# TPCC register map
Vendor: Texas Instruments
Registers are 32-bit, read-write, reset values left out (the file's numbers can be read two ways) unless marked. A register's access mark holds for its fields unless they carry their own. Offsets are as the file gives them; [hi:lo] are bit positions; {n}, {i} and the like mark numbered series; 'fields as' and 'values as' point back to an identical list.

## TPCC (part 2 of 2)
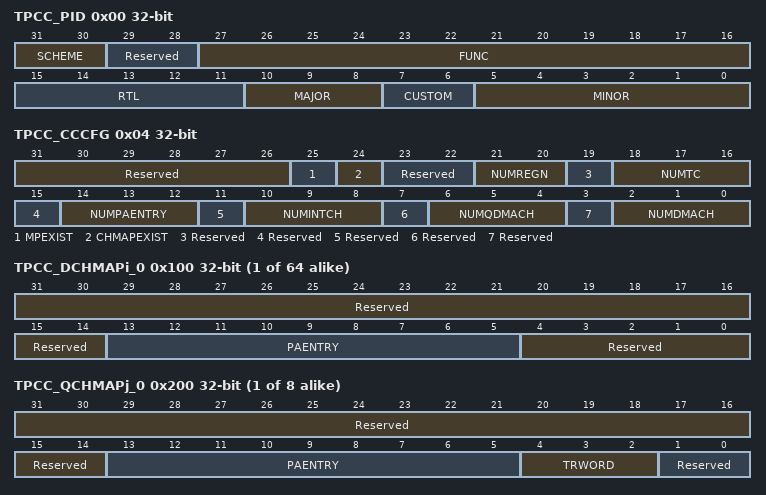
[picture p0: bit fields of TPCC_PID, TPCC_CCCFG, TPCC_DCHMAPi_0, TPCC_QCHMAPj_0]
0x00 TPCC_PID ro — Peripheral ID Register
  [31:30] SCHEME — PID scheme:Used to distinguish between old ID scheme and current.Spare bit to encode future schemes EDMA uses new scheme, indicated with value of 0x1. .
  [29:28] Reserved — Read returns 0.
  [27:16] FUNC — Function indicates a software-compatible module family.
  [15:11] RTL — RTL version
  [10:8] MAJOR — Major revision
  [7:6] CUSTOM — Custom revision field: Not used on this version of EDMA.
  [5:0] MINOR — Minor revision
0x04 TPCC_CCCFG ro — CC Configuration Register
  [31:26] Reserved — Read returns 0.
  [25] MPEXIST — Memory Protection ExistenceMPEXIST = 0: No memory protection.MPEXIST = 1: Memory Protection logic included.
  [24] CHMAPEXIST — Channel Mapping ExistenceCHMAPEXIST = 0: No Channel mapping.CHMAPEXIST = 1: Channel mapping logic included.
  [23:22] Reserved — Read returns 0.
  [21:20] NUMREGN — Number of MP and Shadow regions
    0=NUMREGN_0_r (0 Regions); 1=NUMREGN_1_r (2 Regions); 2=NUMREGN_2_r (4 Regions); 3=NUMREGN_3_r (8 Regions)
  [19] Reserved — Read returns 0.
  [18:16] NUMTC — Number of Queues/Number of TCs
    {v}=NUMTC_{v}_r ({v+1} TC/Event Queue) (v=0..7)
  [15] Reserved — Read returns 0.
  [14:12] NUMPAENTRY — Number of PaRAM entries
    0=NUMPAENTRY_0_r (16 entries); 1=NUMPAENTRY_1_r (32 entries (unsupported setting)); 2=NUMPAENTRY_2_r (64 entries); 3=NUMPAENTRY_3_r (128 entries); 4=NUMPAENTRY_4_r (256 entries); 5=NUMPAENTRY_5_r (512 entries)
  [11] Reserved — Read returns 0.
  [10:8] NUMINTCH — Number of Interrupt Channels
    1=NUMINTCH_1_r (8 Interrupt channels); 2=NUMINTCH_2_r (16 Interrupt channels); 3=NUMINTCH_3_r (32 Interrupt channels); 4=NUMINTCH_4_r (64 Interrupt channels)
  [7] Reserved — Read returns 0.
  [6:4] NUMQDMACH — Number of QDMA Channels
    0=NUMQDMACH_0_r (No QDMA Channels); 1=NUMQDMACH_1_r (2 QDMA Channels); 2=NUMQDMACH_2_r (4 QDMA Channels); 3=NUMQDMACH_3_r (6 QDMA Channels); 4=NUMQDMACH_4_r (8 QDMA Channels)
  [3] Reserved — Read returns 0.
  [2:0] NUMDMACH — Number of DMA Channels
    0=NUMDMACH_0_r (No DMA Channels); 1=NUMDMACH_1_r (4 DMA Channels); 2=NUMDMACH_2_r (8 DMA Channels); 3=NUMDMACH_3_r (16 DMA Channels); 4=NUMDMACH_4_r (32 DMA Channels); 5=NUMDMACH_5_r (64 DMA Channels)
{0x100+4i} TPCC_DCHMAPi_{i} (i=0..63) — DMA Channel i Mapping Register
  [31:14] Reserved — Write 0s for future compatibility.Read returns 0.
  [13:5] PAENTRY — PaRAM Entry number for DMA Channel i.
  [4:0] Reserved — Write 0s for future compatibility.Read returns 0.
{0x200+4i} TPCC_QCHMAPj_{i} (i=0..7) — QDMA Channel i Mapping Register
  [31:14] Reserved — Write 0s for future compatibility.Read returns 0.
  [13:5] PAENTRY — PaRAM Entry number for QDMA Channel i.
  [4:2] TRWORD — TRWORD points to the specific trigger word of the PaRAM Entry defined by PAENTRY. A write to the trigger word results in a QDMA Event being recognized.
  [1:0] Reserved — Write 0s for future compatibility.Read returns 0.
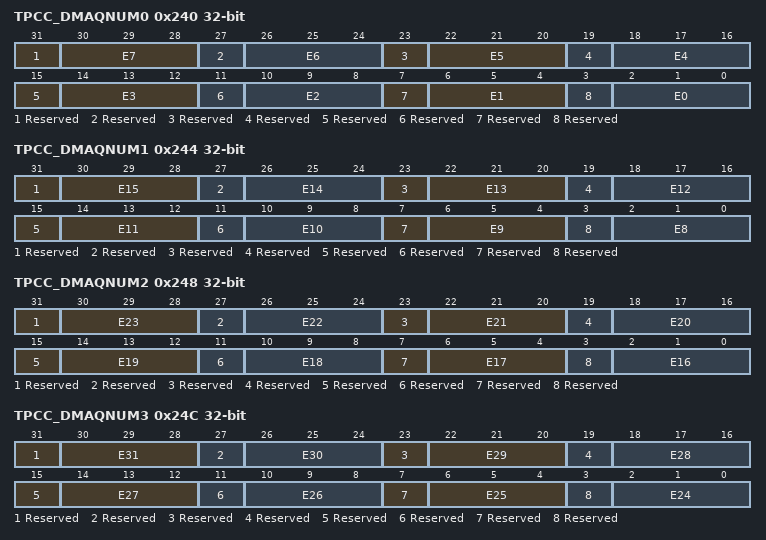
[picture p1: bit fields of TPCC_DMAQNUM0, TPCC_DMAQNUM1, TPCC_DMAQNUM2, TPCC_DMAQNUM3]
0x240 TPCC_DMAQNUM0 — DMA Queue Number Register 0Contains the Event queue number to be used for the corresponding DMA Channel.
  [31] Reserved — Write 0s for future compatibility.Read returns 0.
  [4n+2:4n] E{n} (n=0..7) — DMA Queue Number for event #{n}Others: Not applicable for IVA2.2 .
    0=Event En is queued on Q0; 1=Event En is queued on Q1
  [27] Reserved — Write 0s for future compatibility.Read returns 0.
  [23] Reserved — Write 0s for future compatibility.Read returns 0.
  [19] Reserved — Write 0s for future compatibility.Read returns 0.
  [15] Reserved — Write 0s for future compatibility.Read returns 0.
  [11] Reserved — Write 0s for future compatibility.Read returns 0.
  [7] Reserved — Write 0s for future compatibility.Read returns 0.
  [3] Reserved — Write 0s for future compatibility.Read returns 0.
0x244 TPCC_DMAQNUM1 — DMA Queue Number Register 1Contains the Event queue number to be used for the corresponding DMA Channel.
  [31] Reserved — Write 0s for future compatibility.Read returns 0.
  [4n-30:4n-32] E{n} (n=8..15) — DMA Queue Number for event #{n}Others: Not applicable for IVA2.2 .
    0=Event En is queued on Q0; 1=Event En is queued on Q1
  [27] Reserved — Write 0s for future compatibility.Read returns 0.
  [23] Reserved — Write 0s for future compatibility.Read returns 0.
  [19] Reserved — Write 0s for future compatibility.Read returns 0.
  [15] Reserved — Write 0s for future compatibility.Read returns 0.
  [11] Reserved — Write 0s for future compatibility.Read returns 0.
  [7] Reserved — Write 0s for future compatibility.Read returns 0.
  [3] Reserved — Write 0s for future compatibility.Read returns 0.
0x248 TPCC_DMAQNUM2 — DMA Queue Number Register 2Contains the Event queue number to be used for the corresponding DMA Channel.
  [31] Reserved — Write 0s for future compatibility.Read returns 0.
  [4n-62:4n-64] E{n} (n=16..23) — DMA Queue Number for event #{n}Others: Not applicable for IVA2.2 .
    0=Event En is queued on Q0; 1=Event En is queued on Q1
  [27] Reserved — Write 0s for future compatibility.Read returns 0.
  [23] Reserved — Write 0s for future compatibility.Read returns 0.
  [19] Reserved — Write 0s for future compatibility.Read returns 0.
  [15] Reserved — Write 0s for future compatibility.Read returns 0.
  [11] Reserved — Write 0s for future compatibility.Read returns 0.
  [7] Reserved — Write 0s for future compatibility.Read returns 0.
  [3] Reserved — Write 0s for future compatibility.Read returns 0.
0x24C TPCC_DMAQNUM3 — DMA Queue Number Register 3Contains the Event queue number to be used for the corresponding DMA Channel.
  [31] Reserved — Write 0s for future compatibility.Read returns 0.
  [4n-94:4n-96] E{n} (n=24..31) — DMA Queue Number for event #{n}Others: Not applicable for IVA2.2 .
    0=Event En is queued on Q0; 1=Event En is queued on Q1
  [27] Reserved — Write 0s for future compatibility.Read returns 0.
  [23] Reserved — Write 0s for future compatibility.Read returns 0.
  [19] Reserved — Write 0s for future compatibility.Read returns 0.
  [15] Reserved — Write 0s for future compatibility.Read returns 0.
  [11] Reserved — Write 0s for future compatibility.Read returns 0.
  [7] Reserved — Write 0s for future compatibility.Read returns 0.
  [3] Reserved — Write 0s for future compatibility.Read returns 0.
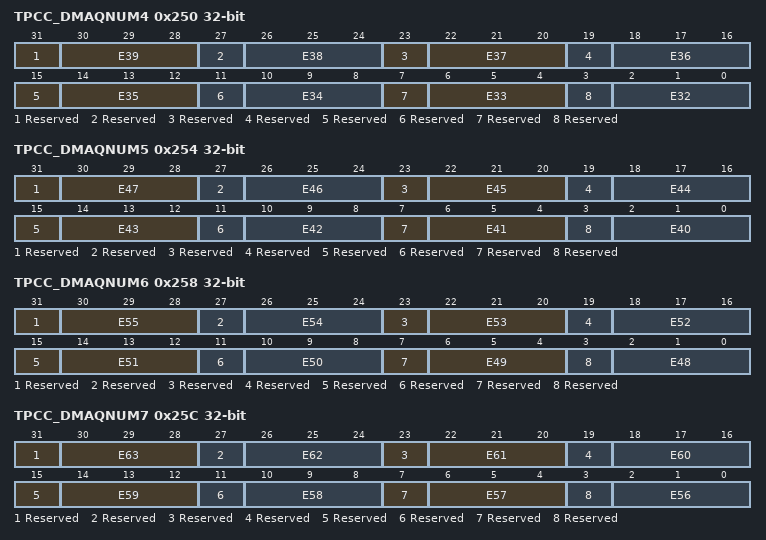
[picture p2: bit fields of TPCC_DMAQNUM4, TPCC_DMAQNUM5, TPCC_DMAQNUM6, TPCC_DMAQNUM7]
0x250 TPCC_DMAQNUM4 — DMA Queue Number Register 4Contains the Event queue number to be used for the corresponding DMA Channel.
  [31] Reserved — Write 0s for future compatibility.Read returns 0.
  [4n-126:4n-128] E{n} (n=32..39) — DMA Queue Number for event #{n}Others: Not applicable for IVA2.2 .
    0=Event En is queued on Q0; 1=Event En is queued on Q1
  [27] Reserved — Write 0s for future compatibility.Read returns 0.
  [23] Reserved — Write 0s for future compatibility.Read returns 0.
  [19] Reserved — Write 0s for future compatibility.Read returns 0.
  [15] Reserved — Write 0s for future compatibility.Read returns 0.
  [11] Reserved — Write 0s for future compatibility.Read returns 0.
  [7] Reserved — Write 0s for future compatibility.Read returns 0.
  [3] Reserved — Write 0s for future compatibility.Read returns 0.
0x254 TPCC_DMAQNUM5 — DMA Queue Number Register 5Contains the Event queue number to be used for the corresponding DMA Channel.
  [31] Reserved — Write 0s for future compatibility.Read returns 0.
  [4n-158:4n-160] E{n} (n=40..47) — DMA Queue Number for event #{n}Others: Not applicable for IVA2.2 .
    0=Event En is queued on Q0; 1=Event En is queued on Q1
  [27] Reserved — Write 0s for future compatibility.Read returns 0.
  [23] Reserved — Write 0s for future compatibility.Read returns 0.
  [19] Reserved — Write 0s for future compatibility.Read returns 0.
  [15] Reserved — Write 0s for future compatibility.Read returns 0.
  [11] Reserved — Write 0s for future compatibility.Read returns 0.
  [7] Reserved — Write 0s for future compatibility.Read returns 0.
  [3] Reserved — Write 0s for future compatibility.Read returns 0.
0x258 TPCC_DMAQNUM6 — DMA Queue Number Register 6Contains the Event queue number to be used for the corresponding DMA Channel.
  [31] Reserved — Write 0s for future compatibility.Read returns 0.
  [4n-190:4n-192] E{n} (n=48..55) — DMA Queue Number for event #{n}Others: Not applicable for IVA2.2 .
    0=Event En is queued on Q0; 1=Event En is queued on Q1
  [27] Reserved — Write 0s for future compatibility.Read returns 0.
  [23] Reserved — Write 0s for future compatibility.Read returns 0.
  [19] Reserved — Write 0s for future compatibility.Read returns 0.
  [15] Reserved — Write 0s for future compatibility.Read returns 0.
  [11] Reserved — Write 0s for future compatibility.Read returns 0.
  [7] Reserved — Write 0s for future compatibility.Read returns 0.
  [3] Reserved — Write 0s for future compatibility.Read returns 0.
0x25C TPCC_DMAQNUM7 — DMA Queue Number Register 7Contains the Event queue number to be used for the corresponding DMA Channel.
  [31] Reserved — Write 0s for future compatibility.Read returns 0.
  [4n-222:4n-224] E{n} (n=56..63) — DMA Queue Number for event #{n}Others: Not applicable for IVA2.2 .
    0=Event En is queued on Q0; 1=Event En is queued on Q1
  [27] Reserved — Write 0s for future compatibility.Read returns 0.
  [23] Reserved — Write 0s for future compatibility.Read returns 0.
  [19] Reserved — Write 0s for future compatibility.Read returns 0.
  [15] Reserved — Write 0s for future compatibility.Read returns 0.
  [11] Reserved — Write 0s for future compatibility.Read returns 0.
  [7] Reserved — Write 0s for future compatibility.Read returns 0.
  [3] Reserved — Write 0s for future compatibility.Read returns 0.
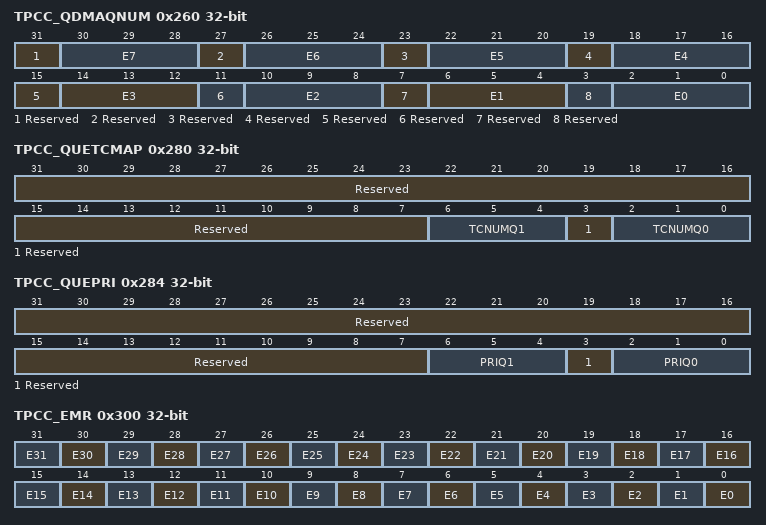
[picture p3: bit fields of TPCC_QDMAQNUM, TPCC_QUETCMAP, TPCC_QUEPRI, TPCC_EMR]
0x260 TPCC_QDMAQNUM — QDMA Queue Number RegisterContains the Event queue number to be used for the corresponding QDMA Channel.
  [31] Reserved — Write 0s for future compatibility.Read returns 0.
  [30:28] E7 — QDMA Queue Number for event #7Others: Not applicable for IVA2.2 .
    0=Event En is queued on Q0; 1=Event En is queued on Q1
  [27] Reserved — Write 0s for future compatibility.Read returns 0.
  [26:24] E6 — QDMA Queue Number for event #6Others: Not applicable for IVA2.2 .
    0=Event En is queued on Q0; 1=Event En is queued on Q1
  [23] Reserved — Write 0s for future compatibility.Read returns 0.
  [22:20] E5 — QDMA Queue Number for event #5others: Not applicable for IVA2.2 .
    0=Event En is queued on Q0; 1=Event En is queued on Q1
  [19] Reserved — Write 0s for future compatibility.Read returns 0.
  [4n+2:4n] E{n} (n=0..4) — QDMA Queue Number for event #{n}Others: Not applicable for IVA2.2 .
    0=Event En is queued on Q0; 1=Event En is queued on Q1
  [15] Reserved — Write 0s for future compatibility.Read returns 0.
  [11] Reserved — Write 0s for future compatibility.Read returns 0.
  [7] Reserved — Write 0s for future compatibility.Read returns 0.
  [3] Reserved — Write 0s for future compatibility.Read returns 0.
0x280 TPCC_QUETCMAP — Queue to TC Mapping
  [31:7] Reserved — Write 0s for future compatibility.Read returns 0.
  [6:4] TCNUMQ1 — TC Number for Queue 1:Defines the TC number that Event Queue 1 TRs are written to.Others: Not applicable for IVA2.2 .
    0=TRs from this queue are routed to TPTC0; 1=TRs from this queue are routed to TPTC1
  [3] Reserved — Write 0s for future compatibility.Read returns 0.
  [2:0] TCNUMQ0 — TC Number for Queue 0:Defines the TC number that Event Queue 0 TRs are written to.Others: Not applicable for IVA2.2 .
    values as TCNUMQ1
0x284 TPCC_QUEPRI — Queue Priority
  [31:7] Reserved — Write 0s for future compatibility.Read returns 0.
  [6:4] PRIQ1 — Priority Level for Queue 1Dictates the priority level used for the OPTIONS field programmation for Qn TRs. Sets the priority used for TC read and write commands.
    0=Priority 0 - Highest priority; {v}=Priority {v} (v=1..6); 7=Priority 7 - Lowest Priority
  [3] Reserved — Write 0s for future compatibility. Read returns 0.
  [2:0] PRIQ0 — Priority Level for Queue 0 Dictates the priority level used for the OPTIONS field programmation for Qn TRs. Sets the priority used for TC read and write commands.
    values as PRIQ1
0x300 TPCC_EMR ro — Event Missed Register: The Event Missed register is set if 2 events are received without the first event being cleared or if a Null TR is serviced. Chained events (CER), Set Events (ESR), and normal events (ER) are treated individually. If any bit in the EMR register is set (and all errors (including QEMR/CCERR)were previously clear), then an error will be signaled with TPCC error interrupt.
  [n] E{n} (n=0..31) — Event Missed #{n}
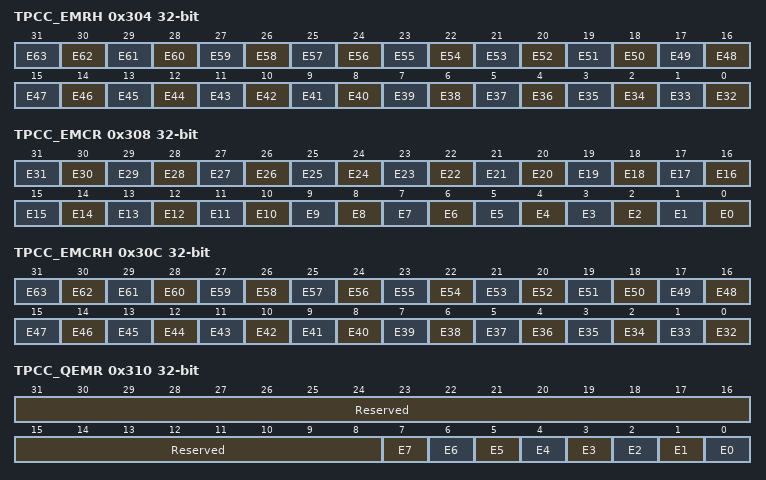
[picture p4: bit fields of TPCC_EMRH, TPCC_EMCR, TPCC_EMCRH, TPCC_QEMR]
0x304 TPCC_EMRH ro — Event Missed Register (High Part):
  [n-32] E{n} (n=32..63) — Event Missed #{n}
0x308 TPCC_EMCR wo — Event Missed Clear Register: CPU write of 1 to the EMCR.En bit causes the EMR.En bit to be cleared.CPU write of 0 has no effect.All error bits must be cleared before additional error interrupts will be asserted by CC.
  [n] E{n} (n=0..31) — Event Missed Clear #{n}
0x30C TPCC_EMCRH wo — Event Missed Clear Register (High Part): CPU write of 1 to the EMCR.En bit causes the EMR.En bit to be cleared.CPU write of 0 has no effect.All error bits must be cleared before additional error interrupts will be asserted by CC.
  [n-32] E{n} (n=32..63) — Event Missed Clear #{n}
0x310 TPCC_QEMR ro — QDMA Event Missed Register: The QDMA Event Missed register is set if 2 QDMA events are detected without the first event being cleared or if a Null TR is serviced.. If any bit in the QEMR register is set (and all errors (including EMR/CCERR) were previously clear), then an error will be signaled with TPCC error interrupt.
  [31:8] Reserved — Read returns 0.
  [n] E{n} (n=0..7) — Event Missed #{n}
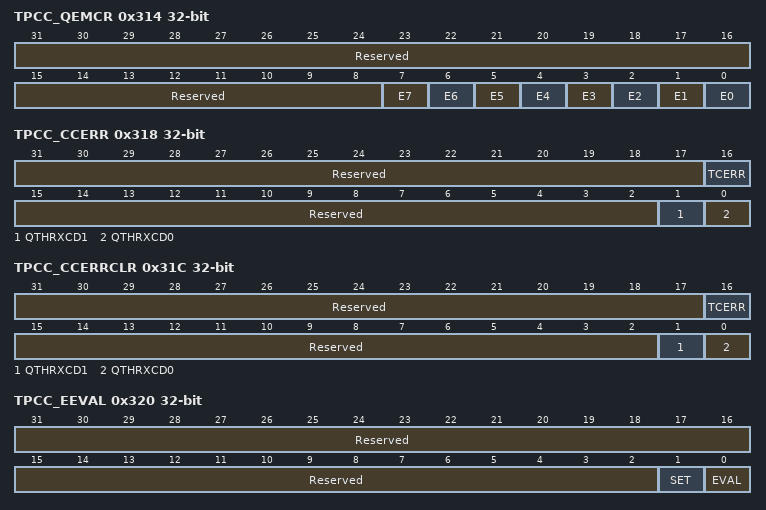
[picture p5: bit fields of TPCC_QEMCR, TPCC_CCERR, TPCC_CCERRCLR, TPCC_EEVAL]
0x314 TPCC_QEMCR wo — QDMA Event Missed Clear Register:CPU write of 1 to the QEMCR.En bit causes the QEMR.En bit to be cleared.CPU write of 0 has no effect.All error bits must be cleared before additional error interrupts will be asserted by CC.
  [31:8] Reserved — Write 0s for future compatibility.
  [n] E{n} (n=0..7) — Event Missed Clear #{n}
0x318 TPCC_CCERR ro — CC Error Register
  [31:17] Reserved — Read returns 0.
  [16] TCERR — Transfer Completion Code Error: TCCERR = 0: Total number of allowed TCCs outstanding has not been reached.TCCERR = 1: Total number of allowed TCCs has been reached. TCCERR can be cleared by writing 1 to corresponding bit in CCERRCLR register. If any bit in the CCERR register is set (and all errors were previously clear), then an error will be signaled with TPCC error interrupt.
  [15:2] Reserved — Read returns 0.
  [1] QTHRXCD1 — Queue Threshold Error for Q1: QTHRXCD1 = 0: Watermark/threshold has not been exceeded.QTHRXCD1 = 1: Watermark/threshold has been exceeded. CCERR.QTHRXCD1 can be cleared by writing 1 to corresponding bit in CCERRCLR register. If any bit in the CCERR register is set (and all errors (including EMR/QEMR) were previously clear), then an error will be signaled with the TPCC error interrupt.
  [0] QTHRXCD0 — Queue Threshold Error for Q0: QTHRXCD0 = 0: Watermark/threshold has not been exceeded.QTHRXCD0 = 1: Watermark/threshold has been exceeded. CCERR.QTHRXCD0 can be cleared by writing 1 to corresponding bit in CCERRCLR register. If any bit in the CCERR register is set (and all errors (including EMR/QEMR) were previously clear), then an error will be signaled with the TPCC error interrupt.
0x31C TPCC_CCERRCLR wo — CC Error Clear Register
  [31:17] Reserved — Write 0s for future compatibility.
  [16] TCERR — Clear Error for CCERR.TCERR: Write of 1 clears the value of CCERR bit N.Writes of 0 have no effect.
  [15:2] Reserved — Write 0s for future compatibility.
  [1] QTHRXCD1 — Clear error for CCERR.QTHRXCD1: Write of 1 clears the values of QSTAT1.WM, QSTAT1.THRXCD, CCERR.QTHRXCD1Writes of 0 have no effect.
  [0] QTHRXCD0 — Clear error for CCERR.QTHRXCD0: Write of 1 clears the values of QSTAT0.WM, QSTAT0.THRXCD, CCERR.QTHRXCD0Writes of 0 have no effect.
0x320 TPCC_EEVAL wo — Error Eval Register
  [31:2] Reserved — Write 0s for future compatibility.
  [1] SET — Error Interrupt Set: CPU write of 1 to the SET bit causes the TPCC error interrupt to be pulsed regardless of state of EMR/EMRH, QEMR, or CCERR.CPU write of 0 has no effect.
  [0] EVAL — Error Interrupt Evaluate: CPU write of 1 to the EVAL bit causes the TPCC error interrupt to be pulsed if any errors have not been cleared in the EMR/EMRH, QEMR, or CCERR registers.CPU write of 0 has no effect.
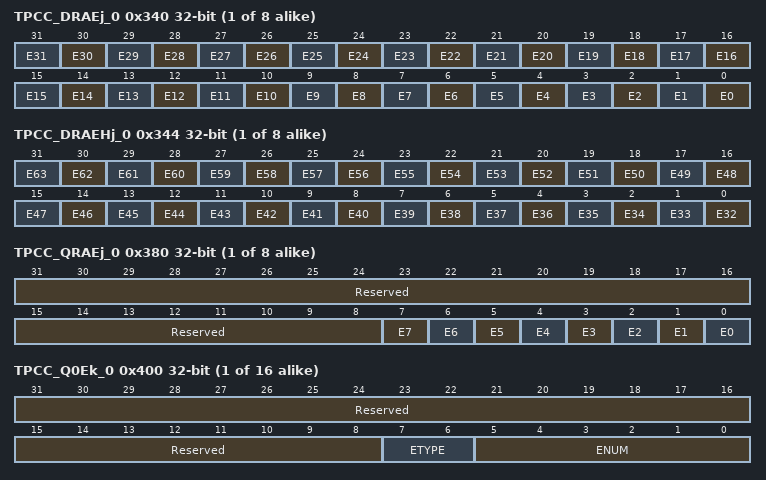
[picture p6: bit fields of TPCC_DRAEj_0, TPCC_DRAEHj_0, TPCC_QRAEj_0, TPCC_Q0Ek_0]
{0x340+8i} TPCC_DRAEj_{i} (i=0..7) — DMA Region Access enable for bit N in Region i: En = 0: Accesses through Region i address space to Bit N in any DMA Channel Register are not allowed. Reads will return b0 on Bit N and writes will not modify the state of bit N. Enabled interrupt bits for bit N do not contribute to the generation of the TPCC region i interrupt.En = 1: Accesses through Region i address space to Bit N in any DMA Channel Register are allowed. Reads will return the value from Bit N and writes will modify the state of bit N. Enabled interrupt bits for bit N do contribute to the generation of the TPCC region i interrupt.
  [n] E{n} (n=0..31) — DMA Region Access enable for Region i, bit #{n}
{0x344+8i} TPCC_DRAEHj_{i} (i=0..7) — DMA Region Access enable for bit N in Region M: En = 0: Accesses through Region i address space to Bit N in any DMA Channel Register are not allowed. Reads will return b0 on Bit N and writes will not modify the state of bit N. Enabled interrupt bits for bit N do not contribute to the generation of the TPCC region i interrupt.En = 1: Accesses through Region i address space to Bit N in any DMA Channel Register are allowed. Reads will return the value from Bit N and writes will modify the state of bit N. Enabled interrupt bits for bit N do contribute to the generation of the TPCC region i interrupt.
  [n-32] E{n} (n=32..63) — DMA Region Access enable for Region i, bit #{n}
{0x380+4i} TPCC_QRAEj_{i} (i=0..7) — QDMA Region Access enable for bit N in Region i: En = 0: Accesses through Region i address space to Bit N in any QDMA Channel Register are not allowed. Reads will return b0 on Bit N and writes will not modify the state of bit N. Enabled interrupt bits for bit N do not contribute to the generation of the TPCC region i interrupt.En = 1: Accesses through Region i address space to Bit N in any QDMA Channel Register are allowed. Reads will return the value from Bit N and writes will modify the state of bit N. Enabled interrupt bits for bit N do contribute to the generation of the TPCC region i interrupt.
  [31:8] Reserved — Write 0s for future compatibility.Read returns 0.
  [n] E{n} (n=0..7) — QDMA Region Access enable for Region i, bit #{n}
{0x400+4i} TPCC_Q0Ek_{i} ro (i=0..15) — Event Queue Entry Diagram for Queue j - Entry i (j =0 to1 and i=0 to 15)
  [31:8] Reserved — Read returns 0.
  [7:6] ETYPE — Event Type:Specifies the specific Event Type for the given entry in the Event Queue.
    0=ETYPE_0_r (Event Triggered through ER); 1=ETYPE_1_r (Manual Triggered through ESR); 2=ETYPE_2_r (Chain Triggered through CER); 3=ETYPE_3_r (Auto-Triggered through QER)
  [5:0] ENUM — Event Number:Specifies the specific Event Number for the given entry in the Event Queue. For DMA Channel events (ER/ESR/CER), ENUM will range between 0 and NUM_DMACH (up to 63). For QDMA Channel events (QER), ENUM will range between 0 and NUM_QDMACH (up to 7).
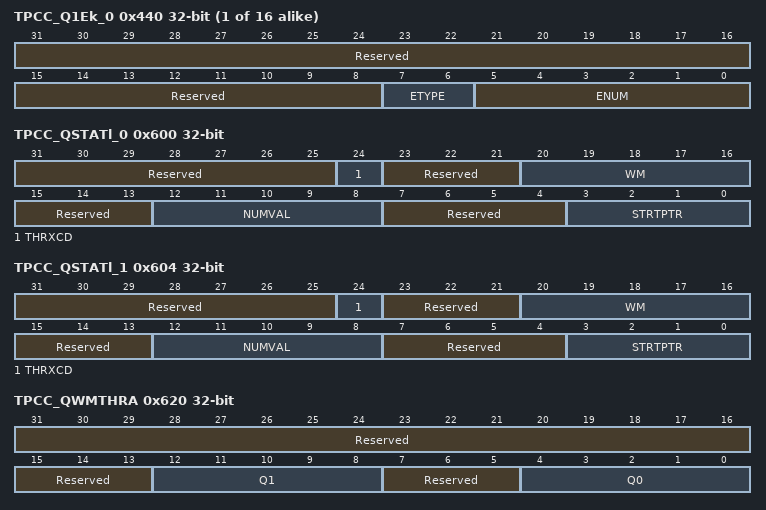
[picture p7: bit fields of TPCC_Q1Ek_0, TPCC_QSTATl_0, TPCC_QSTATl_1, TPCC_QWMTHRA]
{0x440+4i} TPCC_Q1Ek_{i} ro (i=0..15) — Event Queue Entry Diagram for Queue j - Entry i (j =0 to1 and i=0 to 15)
  fields as TPCC_Q0Ek_0
0x600 TPCC_QSTATl_0 ro — QSTATi Register Set
  [31:25] Reserved — Read returns 0.
  [24] THRXCD — Threshold Exceeded: THRXCD = 0: Threshold specified by QWMTHR(A|B).Qn has not been exceeded.THRXCD = 1: Threshold specified by QWMTHR(A|B).Qn has been exceeded. QSTATn.THRXCD is cleared by CCERRCLR.QTHRXCDn
  [23:21] Reserved — Read returns 0.
  [20:16] WM — Watermark for Maximum Queue Usage: Watermark tracks the most entries that have been in QueueN since reset or since the last time that the watermark (WM) was cleared. QSTATn.WM is cleared through CCERR.WMCLRn bit. Legal values = 0x0 (empty) to 0x10 (full)
  [15:13] Reserved — Read returns 0.
  [12:8] NUMVAL — Number of Valid Entries in Queuei: Represents the total number of entries residing in the Queue Manager FIFO at a given instant. Always enabled.Legal values = 0x0 (empty) to 0x10 (full)
  [7:4] Reserved — Read returns 0.
  [3:0] STRTPTR — Start Pointer: Represents the offset to the head entry of Queuei, in units of *entries*. Always enabled.Legal values = 0x0 (0th entry) to 0xF (15th entry)
0x604 TPCC_QSTATl_1 ro — QSTATi Register Set
  fields as TPCC_QSTATl_0
0x620 TPCC_QWMTHRA — Queue Threshold A, for Q[3:0]: CCERR.QTHRXCDn and QSTATn.THRXCD error bit is set when the number of Events in QueueN at an instant in time (visible through QSTATn.NUMVAL) equals or exceeds the value specified by QWMTHRA.Qn.Legal values = 0x0 (ever used?) to 0x10 (ever full?)A value of 0x11 disables threshold errors.
  [31:13] Reserved — Write 0s for future compatibility.Read returns 0.
  [12:8] Q1 — Queue Threshold for Q1 value
  [7:5] Reserved — Write 0s for future compatibility.Read returns 0.
  [4:0] Q0 — Queue Threshold for Q0 value
0x624 TPCC_QWMTHRB — Queue Threshold B, for Q[7:4]: CCERR.QTHRXCDn and QSTATn.THRXCD error bit is set when the number of Events in QueueN at an instant in time (visible through QSTATn.NUMVAL) equals or exceeds the value specified by QWMTHRB.Qn.Legal values = 0x0 (ever used?) to 0x10 (ever full?)A value of 0x11 disables threshold errors.
  [31:0] Reserved — Write 0s for future compatibility.Read returns 0.
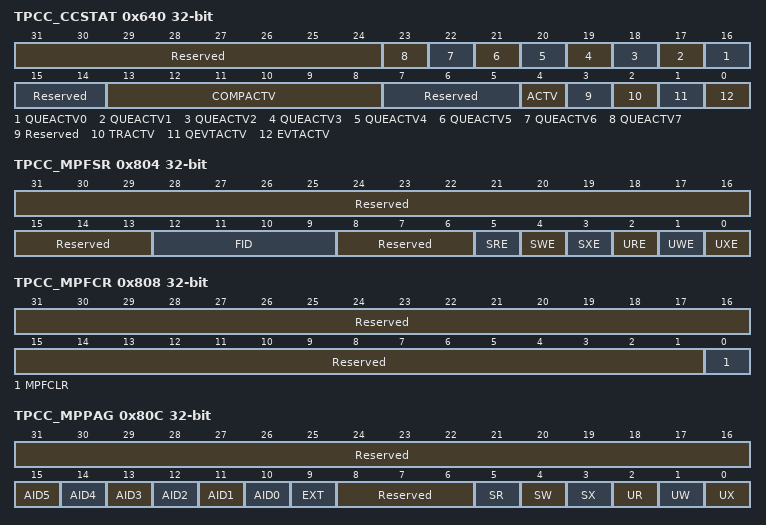
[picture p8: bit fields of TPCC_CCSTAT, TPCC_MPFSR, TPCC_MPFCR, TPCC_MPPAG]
0x640 TPCC_CCSTAT ro — CC Status Register
  [31:24] Reserved — Read returns 0.
  [n+16] QUEACTV{n} (n=0..7) — Queue {n} ActiveQUEACTV{n} = 0: No Evts are queued in Q{n}.QUEACTV{n} = 1: At least one TR is queued in Q{n}.
  [15:14] Reserved — Read returns 0.
  [13:8] COMPACTV — Completion Request Active: Counter that tracks the total number of completion requests submitted to the TC. The counter increments when a TR is submitted with TCINTEN or TCCHEN set to 1. The counter decrements for every valid completion code received from any of the external TCs. The CC will not service newTRs if COMPACTV count is already at the limit. COMPACTV = 0: No completion requests outstanding.COMPACTV = 1: Total of 1 completion request outstanding....COMPACTV = 63 : Total of 63 completion requests are outstanding. No additional TRs will be submitted until count is less than 63.
  [7:5] Reserved — Read returns 0.
  [4] ACTV — Channel Controller Active: Channel Controller Active is a logical-OR of each of the *ACTV signals. The ACTV bit must remain high through the life of a TR.ACTV = 0: Channel is idle.ACTV = 1: Channel is busy.
  [3] Reserved — Read returns 0.
  [2] TRACTV — Transfer Request Active:TRACTV = 0: Transfer Request processing/submission logic is inactive.TRACTV = 1: Transfer Request processing/submission logic is active.
  [1] QEVTACTV — QDMA Event Active:QEVTACTV = 0: No enabled QDMA Events are active within the CC.QEVTACTV = 1: At least one enabled DMA Event(ER &amp; EER, ESR, CER) is active within the CC.
  [0] EVTACTV — DMA Event Active:EVTACTV = 0: No enabled DMA Events are active within the CC.EVTACTV = 1: At least one enabled DMA Event(ER &amp; EER, ESR, CER) is active within the CC.
0x800 TPCC_MPFAR ro — Memory Protection Fault Address
  [31:0] FADDR — Fault Address:32-bit read-only status register containing the faulting address when a memory protection violation is detected. This register can only be cleared through the MPFCR.
0x804 TPCC_MPFSR ro — Memory Protection Fault Status Register
  [31:13] Reserved — Read returns 0.
  [12:9] FID — Faulted ID:FID register contains valid info if any of the MP error bits (UXE, UWE, URE, SXE, SWE, SRE) are non-zero (i.e., if an error has been detected.) The FID field contains the VBus PrivID for the specific request/requestor that resulted in a MP Error.
  [8:6] Reserved — Read returns 0.
  [5] SRE — Supervisor Read Error:SRE = 0: No error detected.SRE = 1: Supervisor level task attempted to Read from a MP Page without SR permissions.
  [4] SWE — Supervisor Write Error:SWE = 0: No error detected.SWE = 1: Supervisor level task attempted to Write to a MP Page without SW permissions.
  [3] SXE — Supervisor Execute Error:SXE = 0: No error detected.SXE = 1: Supervisor level task attempted to Execute from a MP Page without SX permissions.
  [2] URE — User Read Error:URE = 0: No error detected.URE = 1: User level task attempted to Read from a MP Page without UR permissions.
  [1] UWE — User Write Error:UWE = 0: No error detected.UWE = 1: User level task attempted to Write to a MP Page without UW permissions.
  [0] UXE — User Execute Error:UXE = 0: No error detected.UXE = 1: User level task attempted to Execute from a MP Page without UX permissions.
0x808 TPCC_MPFCR wo — Memory Protection Fault Command Register
  [31:1] Reserved — Write 0s for future compatibility.
  [0] MPFCLR — Fault Clear register:CPU write of 1 to the MPFCLR bit causes any error conditions stored in MPFAR and MPFSR registers to be cleared.CPU write of 0 has no effect.
0x80C TPCC_MPPAG — Memory Protection Page Attribute for Global registers
  [31:16] Reserved — Write 0s for future compatibility.Read returns 0.
  [n+10] AID{n} (n=0..5) — Allowed ID {n}:AID{n} = 0: VBus requests with PrivID == {n} are notallowed regardless of permission settings (UW, UR, SW, SR).AID{n} = 1: VBus requests with PrivID == {n} are permitted if access type is allowed as defined by permission settings (UW, UR, SW, SR).
  [9] EXT — External Allowed ID:AIDm = 0: VBus requests with PrivID &gt;= 6 are notallowed regardless of permission settings (UW, UR, SW, SR).AIDm = 1: VBus requests with PrivID &gt;= 6 are permitted if access type is allowed as defined by permission settings (UW, UR, SW, SR).
  [8:6] Reserved — Write reset value for future compatibility. Read returns reset value.
  [5] SR — Supervisor Read permission:SR = 0: Supervisor read accesses are not allowedSR = 1: Supervisor write accesses are allowed
  [4] SW — Supervisor Write permission:SW = 0: Supervisor write accesses are not allowedSW = 1: Supervisor write accesses are allowed
  [3] SX — Supervisor Execute permission:SX = 0: Supervisor execute accesses are not allowedSX = 1: Supervisor execute accesses are allowed
  [2] UR — User Read permission:UR = 0: User read accesses are not allowedUR = 1: User write accesses are allowed
  [1] UW — User Write permission:UW = 0: User write accesses are not allowedUW = 1: User write accesses are allowed
  [0] UX — User Execute permission:UX = 0: User execute accesses are not allowedUX = 1: User execute accesses are allowed
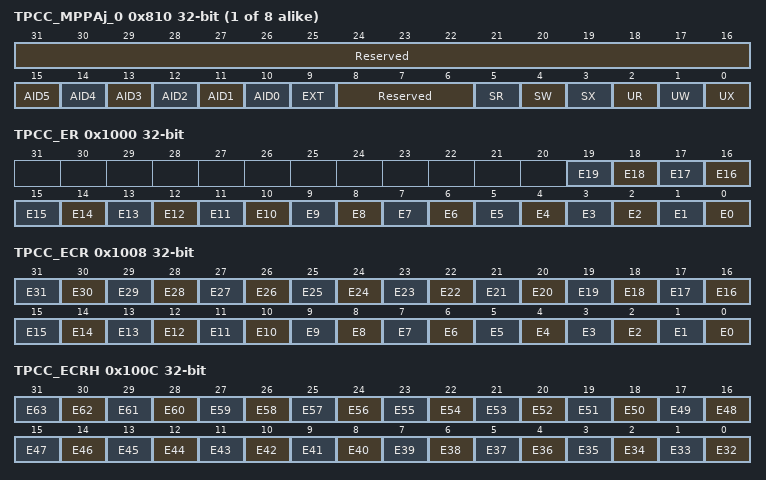
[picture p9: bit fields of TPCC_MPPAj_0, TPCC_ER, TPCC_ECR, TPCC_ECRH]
{0x810+4i} TPCC_MPPAj_{i} (i=0..7) — MP Permission Attribute for DMA Region n
  fields as TPCC_MPPAG
0x1000 TPCC_ER ro — Event Register: If ER.En bit is set and the EER.En bit is also set, then the corresponding DMA channel is prioritized vs. other pending DMA events for submission to the TC. ER.En bit is set when the input event #n transitions from inactive (low) to active (high), regardless of the state of EER.En bit. ER.En bit is cleared when the corresponding event is prioritized and serviced. If the ER.En bit is already set and a new inactive to active transition is detected on the input event #n input AND the corresponding bit in the EER register is set, then the corresponding bit in the Event Missed Register is set. Event N can be cleared through sw by writing 1 to the ECR pseudo-register.
  [n] E{n} (n=0..19) — Event #{n}
0x1008 TPCC_ECR wo — Event Clear Register: CPU write of 1 to the ECR.En bit causes the ER.En bit to be cleared.CPU write of 0 has no effect.
  [n] E{n} (n=0..31) — Event #{n}
0x100C TPCC_ECRH wo — Event Clear Register (High Part): CPU write of 1 to the ECRH.En bit causes the ERH.En bit to be cleared.CPU write of 0 has no effect.
  [n-32] E{n} (n=32..63) — Event #{n}
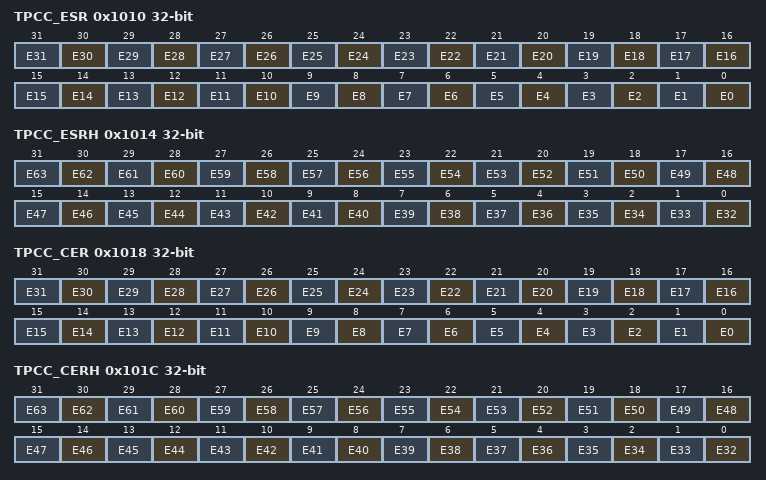
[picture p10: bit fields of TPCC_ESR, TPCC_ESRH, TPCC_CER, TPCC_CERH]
0x1010 TPCC_ESR wo — Event Set Register: CPU write of 1 to the ESR.En bit causes the ER.En bit to be set.CPU write of 0 has no effect.
  [n] E{n} (n=0..31) — Event #{n}
0x1014 TPCC_ESRH wo — Event Set Register (High Part) CPU write of 1 to the ESRH.En bit causes the ERH.En bit to be set.CPU write of 0 has no effect.
  [n-32] E{n} (n=32..63) — Event #{n}
0x1018 TPCC_CER ro — Chained Event Register: If CER.En bit is set (regardless of state of EER.En), then the corresponding DMA channel is prioritized vs. other pending DMA events for submission to the TC. CER.En bit is set when a chaining completion code is returned from one of the TPTCs through the completion interface, or is generated internally through Early Completion path. CER.En bit is cleared when the corresponding event is prioritized and serviced. If the CER.En bit is already set and the corresponding chaining completion code is returned from the TC, then the corresponding bit in the Event Missed Register is set. CER.En cannot be set or cleared through software.
  [n] E{n} (n=0..31) — Event #{n}
0x101C TPCC_CERH ro — Chained Event Register (High Part): If CERH.En bit is set (regardless of state of EERH.En), then the corresponding DMA channel is prioritized vs. other pending DMA events for submission to the TC. CERH.En bit is set when a chaining completion code is returned from one of the TPTCs through the completion interface, or is generated internally through Early Completion path. CERH.En bit is cleared when the corresponding event is prioritized and serviced. If the CERH.En bit is already set and the corresponding chaining completion code is returned from the TC, then the corresponding bit in the Event Missed Register is set. CERH.En cannot be set or cleared through software.
  [n-32] E{n} (n=32..63) — Event #{n}
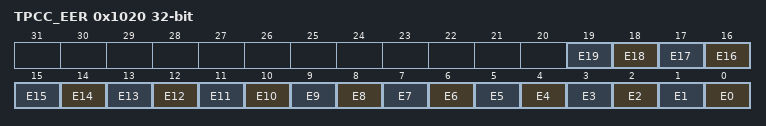
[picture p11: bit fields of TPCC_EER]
0x1020 TPCC_EER ro — Event Enable Register: Enables DMA transfers for ER.En pending events. ER.En is set based on externally asserted events (through tpcc_eventN_pi). This register has no effect on Chained Event Register (CER) or Event Set Register (ESR). Note that if a bit is set in ER.En while EER.En is disabled, no action is taken. If EER.En is enabled at a later point (and ER.En has not been cleared through SW) then the event will be recognized as a valid TR Sync EER.En is not directly writeable. Events can be enabled through writes to EESR and can be disabled through writes to EECR register. EER.En = 0: ER.En is not enabled to trigger DMA transfers. EER.En = 1: ER.En is enabled to trigger DMA transfers.
  [n] E{n} (n=0..19) — Event #{n}
